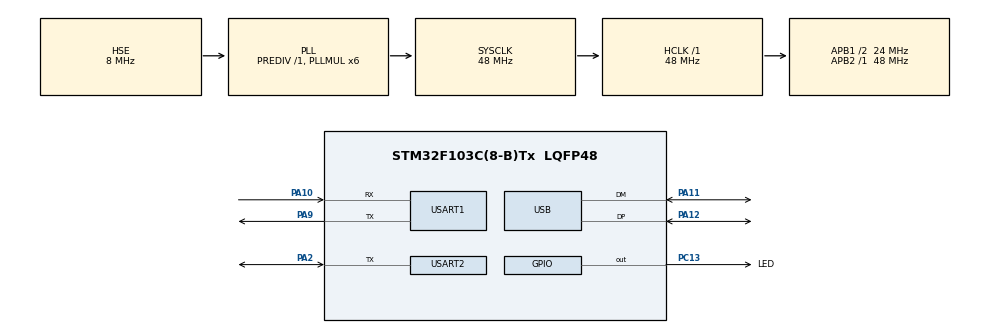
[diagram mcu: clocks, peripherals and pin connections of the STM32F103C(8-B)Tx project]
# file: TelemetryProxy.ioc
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FREERTOS.HEAP_NUMBER=1
FREERTOS.Tasks01=defaultTask,0,64,DefaultTaskFunction;outputTask,0,64,OutputTaskFunction;inputTask,0,64,InputTaskFunction
FREERTOS.configMINIMAL_STACK_SIZE=64
FREERTOS.configTOTAL_HEAP_SIZE=4000
Mcu.Family=STM32F1
Mcu.Name=STM32F103C(8-B)Tx
Mcu.Package=LQFP48
NVIC.PriorityGroup=NVIC_PRIORITYGROUP_4
NVIC.USB_LP_CAN1_RX0_IRQn=true\:5\:0\:false
PA10.Mode=Asynchronous
PA10.Signal=USART1_RX
PA11.Mode=Device
PA11.Signal=USB_DM
PA12.Mode=Device
PA12.Signal=USB_DP
PA2.Mode=Half_duplex(single_wire_mode)
PA2.Signal=USART2_TX
PA9.Mode=Asynchronous
PA9.Signal=USART1_TX
PC13-TAMPER-RTC.GPIO_Label=LED
PC13-TAMPER-RTC.GPIO_ModeDefaultOutputPP=GPIO_MODE_OUTPUT_PP
PC13-TAMPER-RTC.GPIO_Speed=GPIO_SPEED_LOW
PC13-TAMPER-RTC.Signal=GPIO_Output
PD0-OSC_IN.Mode=HSE-External-Oscillator
PD0-OSC_IN.Signal=RCC_OSC_IN
PD1-OSC_OUT.Mode=HSE-External-Oscillator
PD1-OSC_OUT.Signal=RCC_OSC_OUT
ProjectManager.TargetToolchain=TrueSTUDIO 4.3.1
RCC.AHBFreq_Value=48000000
RCC.APB1CLKDivider=RCC_HCLK_DIV2
RCC.APB1Freq_Value=24000000
RCC.APB1TimFreq_Value=48000000
RCC.APB2Freq_Value=48000000
RCC.APB2TimFreq_Value=48000000
RCC.HCLKFreq_Value=48000000
RCC.HSIState=RCC_HSI_ON
RCC.PLLMUL=RCC_PLL_MUL6
RCC.SYSCLKFreq_VALUE=48000000
RCC.SYSCLKSource=RCC_SYSCLKSOURCE_PLLCLK
RCC.USBFreq_Value=48000000
USB_DEVICE.CLASS_NAME-CDC_FS=CDC
USB_DEVICE.USBD_HandleTypeDef-CDC_FS=hUsbDeviceFS
USB_DEVICE.VirtualMode-CDC_FS=Cdc
USB_DEVICE.VirtualModeFS-CDC_FS=Cdc_FS
VP_FREERTOS_VS_ENABLE.Mode=Enabled
VP_USB_DEVICE_VS_USB_DEVICE_CDC_FS.Mode=CDC_FS

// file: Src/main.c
/**
  ******************************************************************************
  * File Name          : main.c
  * Date               : 22/02/2015 21:21:38
  * Description        : Main program body
  ******************************************************************************
  *
  * COPYRIGHT(c) 2015 STMicroelectronics
  *
  * Redistribution and use in source and binary forms, with or without modification,
  * are permitted provided that the following conditions are met:
  *   1. Redistributions of source code must retain the above copyright notice,
  *      this list of conditions and the following disclaimer.
  *   2. Redistributions in binary form must reproduce the above copyright notice,
  *      this list of conditions and the following disclaimer in the documentation
  *      and/or other materials provided with the distribution.
  *   3. Neither the name of STMicroelectronics nor the names of its contributors
  *      may be used to endorse or promote products derived from this software
  *      without specific prior written permission.
  *
  * THIS SOFTWARE IS PROVIDED BY THE COPYRIGHT HOLDERS AND CONTRIBUTORS "AS IS"
  * AND ANY EXPRESS OR IMPLIED WARRANTIES, INCLUDING, BUT NOT LIMITED TO, THE
  * IMPLIED WARRANTIES OF MERCHANTABILITY AND FITNESS FOR A PARTICULAR PURPOSE ARE
  * DISCLAIMED. IN NO EVENT SHALL THE COPYRIGHT HOLDER OR CONTRIBUTORS BE LIABLE
  * FOR ANY DIRECT, INDIRECT, INCIDENTAL, SPECIAL, EXEMPLARY, OR CONSEQUENTIAL
  * DAMAGES (INCLUDING, BUT NOT LIMITED TO, PROCUREMENT OF SUBSTITUTE GOODS OR
  * SERVICES; LOSS OF USE, DATA, OR PROFITS; OR BUSINESS INTERRUPTION) HOWEVER
  * CAUSED AND ON ANY THEORY OF LIABILITY, WHETHER IN CONTRACT, STRICT LIABILITY,
  * OR TORT (INCLUDING NEGLIGENCE OR OTHERWISE) ARISING IN ANY WAY OUT OF THE USE
  * OF THIS SOFTWARE, EVEN IF ADVISED OF THE POSSIBILITY OF SUCH DAMAGE.
  *
  ******************************************************************************
  */

#include "stm32f1xx_hal.h"
#include "cmsis_os.h"
#include "usart.h"
#include "usb_device.h"
#include "gpio.h"

/* USER CODE BEGIN Includes */
#include "usbd_cdc_if.h"
#include "blackboard.h"
/* USER CODE END Includes */

void SystemClock_Config(void);
void MX_FREERTOS_Init(void);

int main(void)
{

  /* MCU Configuration----------------------------------------------------------*/

  /* Reset of all peripherals, Initializes the Flash interface and the Systick. */
  HAL_Init();

  /* Configure the system clock */
  SystemClock_Config();

  /* Initialize all configured peripherals */
  MX_GPIO_Init();
  MX_USART1_UART_Init();
  MX_USART2_UART_Init();

  /* Call init function for freertos objects (in freertos.c) */
  MX_FREERTOS_Init();

  /* Start scheduler */
  osKernelStart();

  /* We should never get here as control is now taken by the scheduler */

  while (1)
  {
  }

}

/** System Clock Configuration
*/
void SystemClock_Config(void)
{

  RCC_OscInitTypeDef RCC_OscInitStruct;
  RCC_ClkInitTypeDef RCC_ClkInitStruct;
  RCC_PeriphCLKInitTypeDef PeriphClkInit;

  RCC_OscInitStruct.OscillatorType = RCC_OSCILLATORTYPE_HSE;
  RCC_OscInitStruct.HSEState = RCC_HSE_ON;
  RCC_OscInitStruct.HSEPredivValue = RCC_HSE_PREDIV_DIV1;
  RCC_OscInitStruct.PLL.PLLState = RCC_PLL_ON;
  RCC_OscInitStruct.PLL.PLLSource = RCC_PLLSOURCE_HSE;
  RCC_OscInitStruct.PLL.PLLMUL = RCC_PLL_MUL6;
  HAL_RCC_OscConfig(&RCC_OscInitStruct);

  RCC_ClkInitStruct.ClockType = RCC_CLOCKTYPE_SYSCLK|RCC_CLOCKTYPE_PCLK1;
  RCC_ClkInitStruct.SYSCLKSource = RCC_SYSCLKSOURCE_PLLCLK;
  RCC_ClkInitStruct.AHBCLKDivider = RCC_SYSCLK_DIV1;
  RCC_ClkInitStruct.APB1CLKDivider = RCC_HCLK_DIV2;
  RCC_ClkInitStruct.APB2CLKDivider = RCC_HCLK_DIV1;
  HAL_RCC_ClockConfig(&RCC_ClkInitStruct, FLASH_LATENCY_1);

  PeriphClkInit.PeriphClockSelection = RCC_PERIPHCLK_USB;
  PeriphClkInit.UsbClockSelection = RCC_USBPLLCLK_DIV1;
  HAL_RCCEx_PeriphCLKConfig(&PeriphClkInit);

  __HAL_RCC_AFIO_CLK_ENABLE();

}

void DefaultTaskFunction(void const * argument)
{
  /* init code for USB_DEVICE */
  MX_USB_DEVICE_Init();

  /* USER CODE BEGIN 5 */
  bbInit();

  bbLock();
  theBlackboard.allSystemsGo = 1;
  bbUnlock();

  /* Infinite loop */
  for(;;)
  {
    osDelay(1000);
    HAL_GPIO_TogglePin(GPIOC, GPIO_PIN_13);
    //uint8_t str[] = "Hello World\r\n";
    //CDC_Transmit_FS(str, sizeof(str));
  }

  /* USER CODE END 5 */

}

/************************ (C) COPYRIGHT STMicroelectronics *****END OF FILE****/

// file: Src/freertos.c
/**
  ******************************************************************************
  * File Name          : freertos.c
  * Date               : 22/02/2015 21:21:37
  * Description        : Code for freertos applications
  ******************************************************************************
  *
  * COPYRIGHT(c) 2015 STMicroelectronics
  *
  * Redistribution and use in source and binary forms, with or without modification,
  * are permitted provided that the following conditions are met:
  *   1. Redistributions of source code must retain the above copyright notice,
  *      this list of conditions and the following disclaimer.
  *   2. Redistributions in binary form must reproduce the above copyright notice,
  *      this list of conditions and the following disclaimer in the documentation
  *      and/or other materials provided with the distribution.
  *   3. Neither the name of STMicroelectronics nor the names of its contributors
  *      may be used to endorse or promote products derived from this software
  *      without specific prior written permission.
  *
  * THIS SOFTWARE IS PROVIDED BY THE COPYRIGHT HOLDERS AND CONTRIBUTORS "AS IS"
  * AND ANY EXPRESS OR IMPLIED WARRANTIES, INCLUDING, BUT NOT LIMITED TO, THE
  * IMPLIED WARRANTIES OF MERCHANTABILITY AND FITNESS FOR A PARTICULAR PURPOSE ARE
  * DISCLAIMED. IN NO EVENT SHALL THE COPYRIGHT HOLDER OR CONTRIBUTORS BE LIABLE
  * FOR ANY DIRECT, INDIRECT, INCIDENTAL, SPECIAL, EXEMPLARY, OR CONSEQUENTIAL
  * DAMAGES (INCLUDING, BUT NOT LIMITED TO, PROCUREMENT OF SUBSTITUTE GOODS OR
  * SERVICES; LOSS OF USE, DATA, OR PROFITS; OR BUSINESS INTERRUPTION) HOWEVER
  * CAUSED AND ON ANY THEORY OF LIABILITY, WHETHER IN CONTRACT, STRICT LIABILITY,
  * OR TORT (INCLUDING NEGLIGENCE OR OTHERWISE) ARISING IN ANY WAY OUT OF THE USE
  * OF THIS SOFTWARE, EVEN IF ADVISED OF THE POSSIBILITY OF SUCH DAMAGE.
  *
  ******************************************************************************
  */

#include "FreeRTOS.h"
#include "task.h"
#include "cmsis_os.h"

osThreadId defaultTaskHandle;
osThreadId outputTaskHandle;
osThreadId inputTaskHandle;

void DefaultTaskFunction(void const * argument);
void OutputTaskFunction(void const * argument);
void InputTaskFunction(void const * argument);

/* Hook prototypes */

/* Init FreeRTOS */

void MX_FREERTOS_Init() {

  /* Create the thread(s) */
  /* definition and creation of defaultTask */
  osThreadDef(defaultTask, DefaultTaskFunction, osPriorityNormal, 0, 64);
  defaultTaskHandle = osThreadCreate(osThread(defaultTask), NULL);

  /* definition and creation of outputTask */
  osThreadDef(outputTask, OutputTaskFunction, osPriorityNormal, 0, 64);
  outputTaskHandle = osThreadCreate(osThread(outputTask), NULL);

  /* definition and creation of inputTask */
  osThreadDef(inputTask, InputTaskFunction, osPriorityNormal, 0, 64);
  inputTaskHandle = osThreadCreate(osThread(inputTask), NULL);

}

/* OutputTaskFunction function */
void OutputTaskFunction(void const * argument)
{
  for(;;)
  {
    osDelay(1);
  }
}

/* InputTaskFunction function */
void InputTaskFunction(void const * argument)
{
  for(;;)
  {
    osDelay(1);
  }
}

/************************ (C) COPYRIGHT STMicroelectronics *****END OF FILE****/
